# WLR089U0 register map
Vendor: Microchip
Registers are 32-bit, read-write, reset 0x0 unless marked. A register's access mark holds for its fields unless they carry their own. Addresses are absolute, and some are shared; only a register's first bit layout is shown; [hi:lo] are bit positions; {n}, {i} and the like mark numbered series; 'fields as' and 'values as' point back to an identical list.

## USB
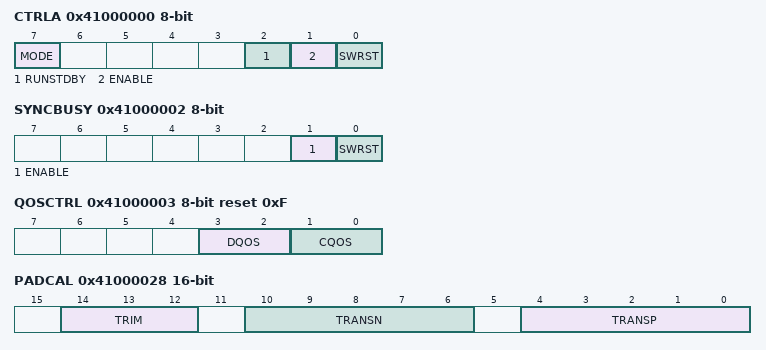
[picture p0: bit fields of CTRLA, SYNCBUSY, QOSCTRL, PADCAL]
0x41000000 CTRLA 8-bit
  [7] MODE — Operating Mode
    0=DEVICE (Device Mode); 1=HOST (Host Mode)
  [2] RUNSTDBY — Run in Standby Mode
  [1] ENABLE
  [0] SWRST — Software Reset
0x41000002 SYNCBUSY 8-bit ro
  [1] ENABLE — Enable Synchronization Busy
  [0] SWRST — Software Reset Synchronization Busy
0x41000003 QOSCTRL 8-bit reset 0xF
  [3:2] DQOS — Data Quality of Service
  [1:0] CQOS — Configuration Quality of Service
0x4100000D FSMSTATUS 8-bit ro reset 0x1
  [6:0] FSMSTATE — Fine State Machine Status
    1=OFF (OFF (L3). It corresponds to the powered-off, disconnected, and disabled state); 2=ON (ON (L0). It corresponds to the Idle and Active states); 4=SUSPEND (SUSPEND (L2)); 8=SLEEP (SLEEP (L1)); 16=DNRESUME (DNRESUME. Down Stream Resume.); 32=UPRESUME (UPRESUME. Up Stream Resume.); 64=RESET (RESET. USB lines Reset.)
0x41000024 DESCADD
  [31:0] DESCADD — Descriptor Address Value
0x41000028 PADCAL 16-bit
  [14:12] TRIM — USB Pad Trim calibration
  [10:6] TRANSN — USB Pad Transn calibration
  [4:0] TRANSP — USB Pad Transp calibration

## DSU
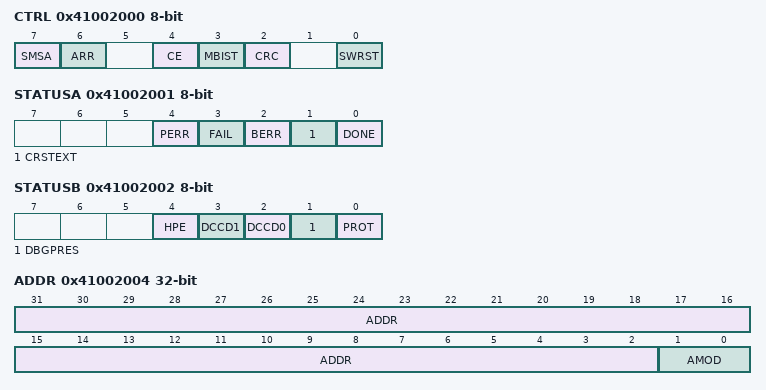
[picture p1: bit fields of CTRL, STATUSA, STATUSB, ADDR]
0x41002000 CTRL 8-bit wo
  [7] SMSA — Start Memory Stream Access
  [6] ARR — Auxiliary Row Read
  [4] CE — Chip-Erase
  [3] MBIST — Memory built-in self-test
  [2] CRC — 32-bit Cyclic Redundancy Code
  [0] SWRST — Software Reset
0x41002001 STATUSA 8-bit
  [4] PERR — Protection Error
  [3] FAIL — Failure
  [2] BERR — Bus Error
  [1] CRSTEXT — CPU Reset Phase Extension
  [0] DONE
0x41002002 STATUSB 8-bit ro
  [4] HPE — Hot-Plugging Enable
  [3] DCCD1 — Debug Communication Channel 1 Dirty
  [2] DCCD0 — Debug Communication Channel 0 Dirty
  [1] DBGPRES — Debugger Present
  [0] PROT — Protected
0x41002004 ADDR
  [31:2] ADDR — Address
  [1:0] AMOD — Access Mode
0x41002008 LENGTH
  [31:2] LENGTH
0x4100200C DATA
0x41002010 DCC0
  [31:0] DATA
0x41002014 DCC1
  [31:0] DATA
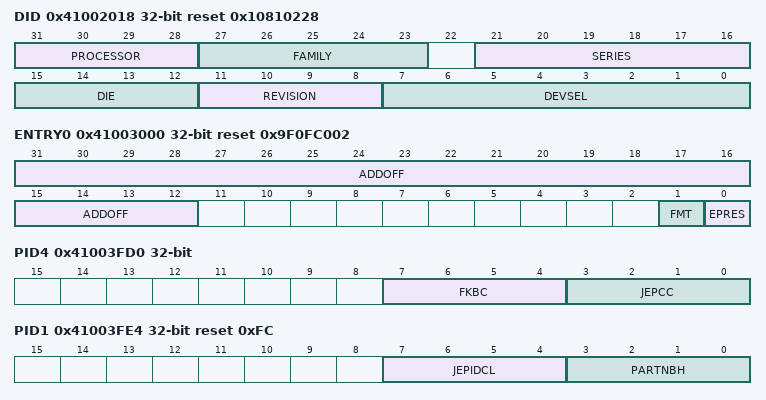
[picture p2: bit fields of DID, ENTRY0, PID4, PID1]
0x41002018 DID ro reset 0x10810228
  [31:28] PROCESSOR
    0=Cortex-M0; 1=Cortex-M0+; 2=Cortex-M3; 3=Cortex-M4
  [27:23] FAMILY
    0=General purpose microcontroller; 1=PicoPower
  [21:16] SERIES
    0=Cortex-M0+ processor, basic feature set; 1=Cortex-M0+ processor, USB
  [15:12] DIE — Die Number
  [11:8] REVISION — Revision Number
  [7:0] DEVSEL — Device Select
0x410020F0 DCFG0
  [31:0] DCFG — Device Configuration
0x410020F4 DCFG1
  [31:0] DCFG — Device Configuration
0x41003000 ENTRY0 ro reset 0x9F0FC002
  [31:12] ADDOFF — Address Offset
  [1] FMT — Format
  [0] EPRES — Entry Present
0x41003004 ENTRY1 ro reset 0x3002
0x41003008 END ro
  [31:0] END — End Marker
0x41003FCC MEMTYPE ro
  [0] SMEMP — System Memory Present
0x41003FD0 PID4 ro
  [7:4] FKBC — 4KB count
  [3:0] JEPCC — JEP-106 Continuation Code
{0x41003FC0+4i} PID{i} ro (i=5..7)
0x41003FE0 PID0 ro reset 0xD0
  [7:0] PARTNBL — Part Number Low
0x41003FE4 PID1 ro reset 0xFC
  [7:4] JEPIDCL — Low part of the JEP-106 Identity Code
  [3:0] PARTNBH — Part Number High
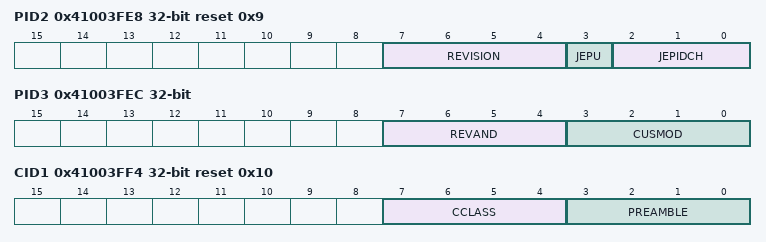
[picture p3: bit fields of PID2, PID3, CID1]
0x41003FE8 PID2 ro reset 0x9
  [7:4] REVISION — Revision Number
  [3] JEPU — JEP-106 Identity Code is used
  [2:0] JEPIDCH — JEP-106 Identity Code High
0x41003FEC PID3 ro
  [7:4] REVAND — Revision Number
  [3:0] CUSMOD — ARM CUSMOD
0x41003FF0 CID0 ro reset 0xD
  [7:0] PREAMBLEB0 — Preamble Byte 0
0x41003FF4 CID1 ro reset 0x10
  [7:4] CCLASS — Component Class
  [3:0] PREAMBLE
0x41003FF8 CID2 ro reset 0x5
  [7:0] PREAMBLEB2 — Preamble Byte 2
0x41003FFC CID3 ro reset 0xB1
  [7:0] PREAMBLEB3 — Preamble Byte 3

## NVMCTRL
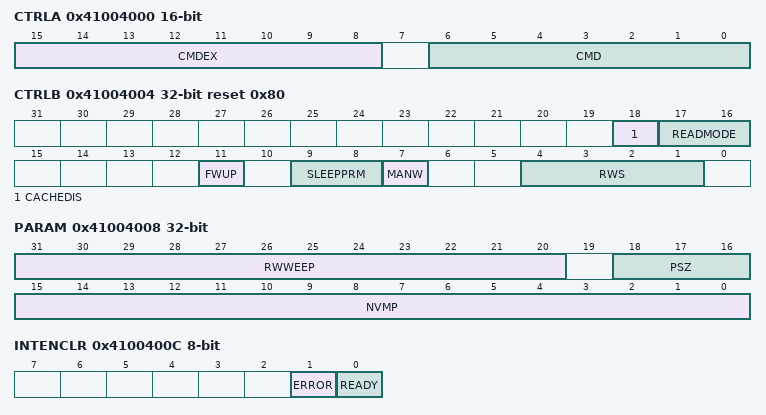
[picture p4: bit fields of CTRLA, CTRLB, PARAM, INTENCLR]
0x41004000 CTRLA 16-bit
  [15:8] CMDEX — Command Execution
    165=KEY (Execution Key)
  [6:0] CMD — Command
    2=ER (Erase Row - Erases the row addressed by the ADDR register.); 4=WP (Write Page - Writes the contents of the page buffer to the page addressed by the ADDR register.); 5=EAR (Erase Auxiliary Row - Erases the auxiliary row addressed by the ADDR register. This command can be given only when the security bit is not set and only to the user configuration row.); 6=WAP (Write Auxiliary Page - Writes the contents of the page buffer to the page addressed by the ADDR register. This command can be given only when the security bit is not set and only to the user configuration row.); 10=SF (Security Flow Command); 15=WL (Write lockbits); 26=RWWEEER (RWW EEPROM area Erase Row - Erases the row addressed by the ADDR register.); 28=RWWEEWP (RWW EEPROM Write Page - Writes the contents of the page buffer to the page addressed by the ADDR register.); 64=LR (Lock Region - Locks the region containing the address location in the ADDR register.); 65=UR (Unlock Region - Unlocks the region containing the address location in the ADDR register.); 66=SPRM (Sets the power reduction mode.); 67=CPRM (Clears the power reduction mode.); 68=PBC (Page Buffer Clear - Clears the page buffer.); 69=SSB (Set Security Bit - Sets the security bit by writing 0x00 to the first byte in the lockbit row.); 70=INVALL (Invalidate all cache lines.)
0x41004004 CTRLB reset 0x80
  [18] CACHEDIS — Cache Disable
  [17:16] READMODE — NVMCTRL Read Mode
    0=NO_MISS_PENALTY (The NVM Controller (cache system) does not insert wait states on a cache miss. Gives the best system performance.); 1=LOW_POWER (Reduces power consumption of the cache system, but inserts a wait state each time there is a cache miss. This mode may not be relevant if CPU performance is required, as the application will be stalled and may lead to increase run time.); 2=DETERMINISTIC (The cache system ensures that a cache hit or miss takes the same amount of time, determined by the number of programmed flash wait states. This mode can be used for real-time applications that require deterministic execution timings.)
  [11] FWUP — fast wake-up
  [9:8] SLEEPPRM — Power Reduction Mode during Sleep
    0=WAKEONACCESS (NVM block enters low-power mode when entering sleep.NVM block exits low-power mode upon first access.); 1=WAKEUPINSTANT (NVM block enters low-power mode when entering sleep.NVM block exits low-power mode when exiting sleep.); 3=DISABLED (Auto power reduction disabled.)
  [7] MANW — Manual Write
  [4:1] RWS — NVM Read Wait States
    0=SINGLE (Single Auto Wait State); 1=HALF (Half Auto Wait State); 2=DUAL (Dual Auto Wait State)
0x41004008 PARAM
  [31:20] RWWEEP — RWW EEPROM Pages
  [18:16] PSZ — Page Size
    0=8 bytes; 1=16 bytes; 2=32 bytes; 3=64 bytes; 4=128 bytes; 5=256 bytes; 6=512 bytes; 7=1024 bytes
  [15:0] NVMP — NVM Pages
0x4100400C INTENCLR 8-bit
  [1] ERROR — Error Interrupt Enable
  [0] READY — NVM Ready Interrupt Enable
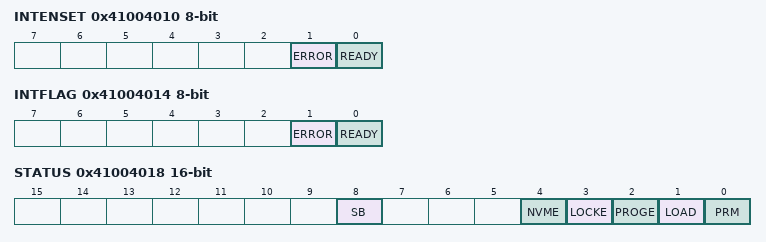
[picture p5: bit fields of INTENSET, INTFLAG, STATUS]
0x41004010 INTENSET 8-bit
  fields as INTENCLR
0x41004014 INTFLAG 8-bit
  [1] ERROR
  [0] READY — NVM Ready
0x41004018 STATUS 16-bit
  [8] SB — Security Bit Status
  [4] NVME — NVM Error
  [3] LOCKE — Lock Error Status
  [2] PROGE — Programming Error Status
  [1] LOAD — NVM Page Buffer Active Loading
  [0] PRM — Power Reduction Mode
0x4100401C ADDR
  [21:0] ADDR — NVM Address
0x41004020 LOCK 16-bit reset not defined
  [15:0] LOCK — Region Lock Bits
